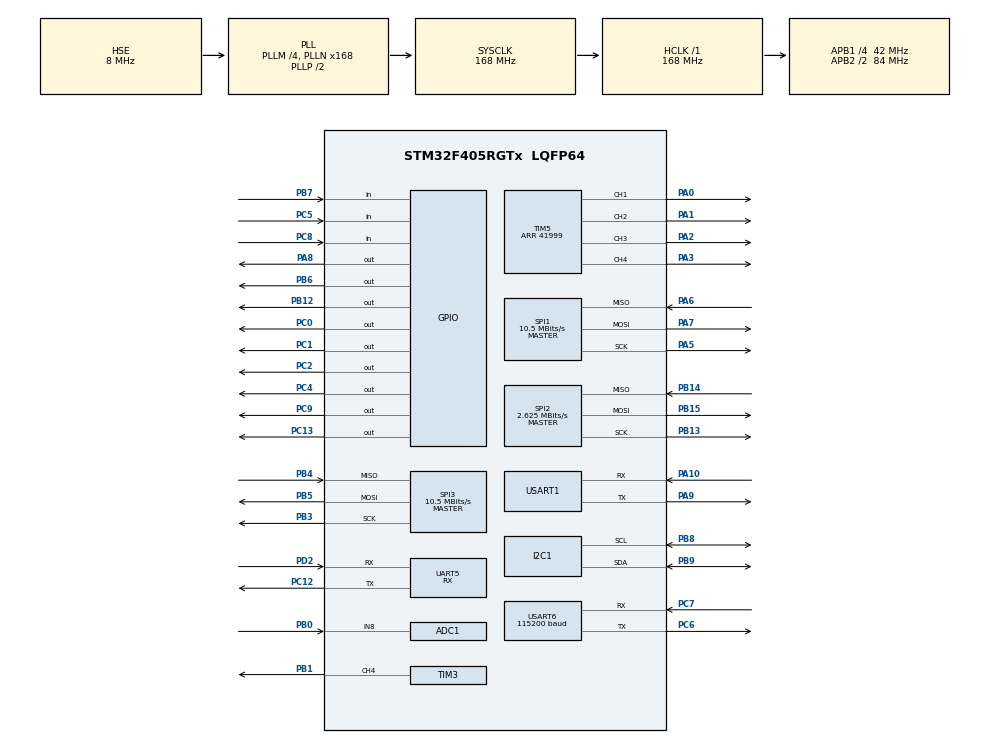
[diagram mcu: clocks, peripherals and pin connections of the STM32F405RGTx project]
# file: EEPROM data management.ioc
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ADC1.Channel-0\#ChannelRegularConversion=ADC_CHANNEL_8
ADC1.ClockPrescaler=ADC_CLOCK_SYNC_PCLK_DIV8
ADC1.ContinuousConvMode=ENABLE
ADC1.DMAContinuousRequests=ENABLE
ADC1.NbrOfConversionFlag=1
ADC1.Rank-0\#ChannelRegularConversion=1
ADC1.SamplingTime-0\#ChannelRegularConversion=ADC_SAMPLETIME_480CYCLES
ADC1.master=1
Dma.ADC1.0.Direction=DMA_PERIPH_TO_MEMORY
Dma.ADC1.0.FIFOMode=DMA_FIFOMODE_DISABLE
Dma.ADC1.0.Instance=DMA2_Stream0
Dma.ADC1.0.MemDataAlignment=DMA_MDATAALIGN_HALFWORD
Dma.ADC1.0.MemInc=DMA_MINC_DISABLE
Dma.ADC1.0.Mode=DMA_CIRCULAR
Dma.ADC1.0.PeriphDataAlignment=DMA_PDATAALIGN_HALFWORD
Dma.ADC1.0.PeriphInc=DMA_PINC_DISABLE
Dma.ADC1.0.Priority=DMA_PRIORITY_LOW
Dma.Request0=ADC1
I2C1.I2C_Mode=I2C_Fast
Mcu.Family=STM32F4
Mcu.Name=STM32F405RGTx
Mcu.Package=LQFP64
NVIC.DMA2_Stream0_IRQn=true\:0\:0\:false\:false\:true\:false\:true\:true
NVIC.PriorityGroup=NVIC_PRIORITYGROUP_4
NVIC.TIM7_IRQn=true\:0\:0\:false\:false\:true\:true\:true\:true
NVIC.UART5_IRQn=true\:0\:0\:false\:false\:true\:true\:true\:true
NVIC.USART1_IRQn=true\:0\:0\:false\:false\:true\:true\:true\:true
NVIC.USART6_IRQn=true\:0\:0\:false\:false\:true\:true\:true\:true
PA0-WKUP.Signal=S_TIM5_CH1
PA1.Signal=S_TIM5_CH2
PA10.Mode=Asynchronous
PA10.Signal=USART1_RX
PA2.Signal=S_TIM5_CH3
PA3.Signal=S_TIM5_CH4
PA5.Mode=Full_Duplex_Master
PA5.Signal=SPI1_SCK
PA6.Mode=Full_Duplex_Master
PA6.Signal=SPI1_MISO
PA7.Mode=Full_Duplex_Master
PA7.Signal=SPI1_MOSI
PA8.Signal=GPIO_Output
PA9.Mode=Asynchronous
PA9.Signal=USART1_TX
PB0.Signal=ADCx_IN8
PB1.Signal=S_TIM3_CH4
PB12.Signal=GPIO_Output
PB13.Mode=Full_Duplex_Master
PB13.Signal=SPI2_SCK
PB14.Mode=Full_Duplex_Master
PB14.Signal=SPI2_MISO
PB15.Mode=Full_Duplex_Master
PB15.Signal=SPI2_MOSI
PB3.Mode=Full_Duplex_Master
PB3.Signal=SPI3_SCK
PB4.Mode=Full_Duplex_Master
PB4.Signal=SPI3_MISO
PB5.Mode=Full_Duplex_Master
PB5.Signal=SPI3_MOSI
PB6.Signal=GPIO_Output
PB7.Signal=GPIO_Input
PB8.Mode=I2C
PB8.Signal=I2C1_SCL
PB9.Mode=I2C
PB9.Signal=I2C1_SDA
PC0.Signal=GPIO_Output
PC1.Signal=GPIO_Output
PC12.Mode=Asynchronous
PC12.Signal=UART5_TX
PC13-ANTI_TAMP.PinState=GPIO_PIN_SET
PC13-ANTI_TAMP.Signal=GPIO_Output
PC2.Signal=GPIO_Output
PC4.Signal=GPIO_Output
PC5.Signal=GPIO_Input
PC6.Mode=Asynchronous
PC6.Signal=USART6_TX
PC7.Mode=Asynchronous
PC7.Signal=USART6_RX
PC8.Signal=GPIO_Input
PC9.Signal=GPIO_Output
PD2.Mode=Asynchronous
PD2.Signal=UART5_RX
PH0-OSC_IN.Mode=HSE-External-Oscillator
PH0-OSC_IN.Signal=RCC_OSC_IN
PH1-OSC_OUT.Mode=HSE-External-Oscillator
PH1-OSC_OUT.Signal=RCC_OSC_OUT
ProjectManager.HeapSize=0x200
ProjectManager.StackSize=0x400
ProjectManager.TargetToolchain=STM32CubeIDE
RCC.48MHZClocksFreq_Value=84000000
RCC.AHBFreq_Value=168000000
RCC.APB1CLKDivider=RCC_HCLK_DIV4
RCC.APB1Freq_Value=42000000
RCC.APB1TimFreq_Value=84000000
RCC.APB2CLKDivider=RCC_HCLK_DIV2
RCC.APB2Freq_Value=84000000
RCC.APB2TimFreq_Value=168000000
RCC.CortexFreq_Value=168000000
RCC.HCLKFreq_Value=168000000
RCC.HSE_VALUE=8000000
RCC.HSI_VALUE=16000000
RCC.LSE_VALUE=32768
RCC.PLLM=4
RCC.PLLN=168
RCC.PLLSourceVirtual=RCC_PLLSOURCE_HSE
RCC.SYSCLKFreq_VALUE=168000000
RCC.SYSCLKSource=RCC_SYSCLKSOURCE_PLLCLK
RCC.VCOOutputFreq_Value=336000000
SH.ADCx_IN8.0=ADC1_IN8,IN8
SH.S_TIM3_CH4.0=TIM3_CH4,PWM Generation4 CH4
SH.S_TIM5_CH1.0=TIM5_CH1,PWM Generation1 CH1
SH.S_TIM5_CH2.0=TIM5_CH2,PWM Generation2 CH2
SH.S_TIM5_CH3.0=TIM5_CH3,PWM Generation3 CH3
SH.S_TIM5_CH4.0=TIM5_CH4,PWM Generation4 CH4
SPI1.BaudRatePrescaler=SPI_BAUDRATEPRESCALER_8
SPI1.CLKPhase=SPI_PHASE_2EDGE
SPI1.CLKPolarity=SPI_POLARITY_HIGH
SPI1.CalculateBaudRate=10.5 MBits/s
SPI1.DataSize=SPI_DATASIZE_8BIT
SPI1.Direction=SPI_DIRECTION_2LINES
SPI1.Mode=SPI_MODE_MASTER
SPI1.VirtualType=VM_MASTER
SPI2.BaudRatePrescaler=SPI_BAUDRATEPRESCALER_16
SPI2.CLKPhase=SPI_PHASE_2EDGE
SPI2.CLKPolarity=SPI_POLARITY_HIGH
SPI2.CalculateBaudRate=2.625 MBits/s
SPI2.Direction=SPI_DIRECTION_2LINES
SPI2.Mode=SPI_MODE_MASTER
SPI2.VirtualType=VM_MASTER
SPI3.BaudRatePrescaler=SPI_BAUDRATEPRESCALER_4
SPI3.CLKPhase=SPI_PHASE_2EDGE
SPI3.CLKPolarity=SPI_POLARITY_HIGH
SPI3.CalculateBaudRate=10.5 MBits/s
SPI3.Direction=SPI_DIRECTION_2LINES
SPI3.Mode=SPI_MODE_MASTER
SPI3.VirtualType=VM_MASTER
TIM3.AutoReloadPreload=TIM_AUTORELOAD_PRELOAD_ENABLE
TIM3.Channel-PWM\ Generation4\ CH4=TIM_CHANNEL_4
TIM3.OCFastMode_PWM-PWM\ Generation4\ CH4=TIM_OCFAST_ENABLE
TIM3.Period=20
TIM3.Prescaler=999
TIM3.Pulse-PWM\ Generation4\ CH4=10
TIM5.AutoReloadPreload=TIM_AUTORELOAD_PRELOAD_ENABLE
TIM5.Channel-PWM\ Generation1\ CH1=TIM_CHANNEL_1
TIM5.Channel-PWM\ Generation2\ CH2=TIM_CHANNEL_2
TIM5.Channel-PWM\ Generation3\ CH3=TIM_CHANNEL_3
TIM5.Channel-PWM\ Generation4\ CH4=TIM_CHANNEL_4
TIM5.OCFastMode_PWM-PWM\ Generation1\ CH1=TIM_OCFAST_ENABLE
TIM5.OCFastMode_PWM-PWM\ Generation2\ CH2=TIM_OCFAST_ENABLE
TIM5.OCFastMode_PWM-PWM\ Generation3\ CH3=TIM_OCFAST_ENABLE
TIM5.OCFastMode_PWM-PWM\ Generation4\ CH4=TIM_OCFAST_ENABLE
TIM5.Period=41999
TIM5.Pulse-PWM\ Generation1\ CH1=0
TIM5.Pulse-PWM\ Generation2\ CH2=0
TIM5.Pulse-PWM\ Generation3\ CH3=0
TIM7.AutoReloadPreload=TIM_AUTORELOAD_PRELOAD_ENABLE
TIM7.Period=1
TIM7.Prescaler=41999
UART5.Mode=MODE_RX
UART5.VirtualMode=Asynchronous
USART1.VirtualMode=VM_ASYNC
USART6.BaudRate=115200
USART6.VirtualMode=VM_ASYNC
VP_TIM3_VS_ClockSourceINT.Mode=Internal
VP_TIM5_VS_ClockSourceINT.Mode=Internal
VP_TIM7_VS_ClockSourceINT.Mode=Enable_Timer
board=custom

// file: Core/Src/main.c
/* USER CODE BEGIN Header */
/**
 ******************************************************************************
 * @file           : main.c
 * @brief          : Main program body
 ******************************************************************************
 * @attention
 *
 * Copyright (c) 2025 STMicroelectronics.
 * All rights reserved.
 *
 * This software is licensed under terms that can be found in the LICENSE file
 * in the root directory of this software component.
 * If no LICENSE file comes with this software, it is provided AS-IS.
 *
 ******************************************************************************
 */
/* USER CODE END Header */
#include "main.h"

/* USER CODE BEGIN Includes */
#include "BNO080.h"
#include "ICM20602.h"
#include "LPS22HH.h"
#include "FS-iA6B.h"
#include "AT24C08.h"
#include "Quaternion.h"
#include <stdio.h>
#include <string.h>
/* USER CODE END Includes */

/* USER CODE BEGIN PTD */
int _write(int file, char *p, int len)
{
	for (int i = 0; i < len; i ++)
	{
		LL_USART_TransmitData8(USART6, *(p + i));
		HAL_Delay(1);
	}
	return len;
}
/* USER CODE END PTD */

/* USER CODE BEGIN PD */
#define X 0.90f // LOW PASS FILTER CONSTANT (CLOSER TO 1 -> STRONGER THE FILTER)
/* USER CODE END PD */

ADC_HandleTypeDef hadc1;
DMA_HandleTypeDef hdma_adc1;

I2C_HandleTypeDef hi2c1;

UART_HandleTypeDef huart1;

/* USER CODE BEGIN PV */
extern uint8_t uart6_rx_flag;
extern uint8_t uart6_rx_data;

extern uint8_t ibus_rx_buf[36];
extern uint8_t ibus_rx_cplt_flag;

extern FSiA6B_iBus iBus;

extern I2C_HandleTypeDef hi2c;

extern uint8_t uart1_rx_data;

uint8_t radio_tx_buf[40];
uint8_t radio_rx_buf[20];
uint8_t radio_rx_cplt_flag;

extern uint8_t tim7_1ms_flag;
extern uint8_t tim7_20ms_flag;
extern uint8_t tim7_100ms_flag;
extern uint8_t tim7_1000ms_flag;

float batVolt;

float roll_in_kp;
float roll_in_ki;
float roll_in_kd;

float roll_out_kp;
float roll_out_ki;
float roll_out_kd;

float pitch_in_kp;
float pitch_in_ki;
float pitch_in_kd;

float pitch_out_kp;
float pitch_out_ki;
float pitch_out_kd;

float yaw_heading_kp;
float yaw_heading_ki;
float yaw_heading_kd;

float yaw_rate_kp;
float yaw_rate_ki;
float yaw_rate_kd;

unsigned char failsafe_flag = 0;
unsigned char low_bat_flag = 0;
/* USER CODE END PV */

void SystemClock_Config(void);
static void MX_GPIO_Init(void);
static void MX_DMA_Init(void);
static void MX_TIM3_Init(void);
static void MX_USART6_UART_Init(void);
static void MX_SPI2_Init(void);
static void MX_SPI1_Init(void);
static void MX_SPI3_Init(void);
static void MX_UART5_Init(void);
static void MX_TIM5_Init(void);
static void MX_I2C1_Init(void);
static void MX_ADC1_Init(void);
static void MX_USART1_UART_Init(void);
static void MX_TIM7_Init(void);
/* USER CODE BEGIN PFP */
void BNO080_Calibration(void);
int iBus_Connection_Status(void);
void ESC_Calibration(void);
int iBus_Throttle_Min(void);
void Encode_MSG_AHRS(unsigned char *radio_tx_buf);
void Encode_MSG_GPS(unsigned char *radio_tx_buf);
void Encode_MSG_PID_Gain(unsigned char *radio_tx_buf, unsigned char id, float p, float i, float d);
/* USER CODE END PFP */

int main(void)
{

	/* USER CODE BEGIN 1 */
	float q[4]; // array to store components of quaternion (x, y, z, w)
	float quatRadianAccuracy;
	unsigned short adcVal;
	short gyro_x_offset = 34, gyro_y_offset = -5, gyro_z_offset = -37;

	unsigned char motor_arm_flag = 0;
	unsigned short iBus_prev_SwA = 0;
	unsigned char iBus_rx_cnt = 0;
	unsigned short ccr1, ccr2, ccr3, ccr4;
	/* USER CODE END 1 */

	/* MCU Configuration--------------------------------------------------------*/

	/* Reset of all peripherals, Initializes the Flash interface and the Systick. */
	HAL_Init();

	/* Configure the system clock */
	SystemClock_Config();

	/* Initialize all configured peripherals */
	MX_GPIO_Init();
	MX_DMA_Init();
	MX_TIM3_Init();
	MX_USART6_UART_Init();
	MX_SPI2_Init();
	MX_SPI1_Init();
	MX_SPI3_Init();
	MX_UART5_Init();
	MX_TIM5_Init();
	MX_I2C1_Init();
	MX_ADC1_Init();
	MX_USART1_UART_Init();
	MX_TIM7_Init();
	/* USER CODE BEGIN 2 */
	/* enable timer for buzzer */
	LL_TIM_EnableCounter(TIM3);

	/* enable interrupt pins */
	LL_USART_EnableIT_RXNE(USART6);
	// TODO: enable interrupt pin for GPS module
	LL_USART_EnableIT_RXNE(UART5);
	// TODO: initialize M8N GPS module
	// initialize timer for generating PWM signals to motors
	LL_TIM_EnableCounter(TIM5);
	LL_TIM_CC_EnableChannel(TIM5, LL_TIM_CHANNEL_CH1);
	LL_TIM_CC_EnableChannel(TIM5, LL_TIM_CHANNEL_CH2);
	LL_TIM_CC_EnableChannel(TIM5, LL_TIM_CHANNEL_CH3);
	LL_TIM_CC_EnableChannel(TIM5, LL_TIM_CHANNEL_CH4);
	// direct memory access for ADC value
	HAL_ADC_Start_DMA(&hadc1, &adcVal, 1);
	HAL_UART_Receive_IT(&huart1, &uart1_rx_data, 1);

	LL_TIM_EnableCounter(TIM7); // 10Hz, 50Hz, 1kHz loop
	LL_TIM_EnableIT_UPDATE(TIM7);

	/* initialize external peripherals (sensors, telemetry) */

	TIM3->PSC = 1000;
	LL_TIM_CC_EnableChannel(TIM3, LL_TIM_CHANNEL_CH4);
	HAL_Delay(60);
	LL_TIM_CC_DisableChannel(TIM3, LL_TIM_CHANNEL_CH4);
	HAL_Delay(60);
	LL_TIM_CC_EnableChannel(TIM3, LL_TIM_CHANNEL_CH4);
	HAL_Delay(60);
	LL_TIM_CC_DisableChannel(TIM3, LL_TIM_CHANNEL_CH4);
	HAL_Delay(60);

	printf("checking sensor connection...\n");

	// initialize 9-axis sensor for rotation vector
	if(BNO080_Initialization())
	{
		LL_TIM_CC_EnableChannel(TIM3, LL_TIM_CHANNEL_CH4);

		TIM3->PSC = 1000;
		HAL_Delay(100);
		TIM3->PSC = 1500;
		HAL_Delay(100);
		TIM3->PSC = 2000;
		HAL_Delay(100);

		LL_TIM_CC_DisableChannel(TIM3, LL_TIM_CHANNEL_CH4);

		printf("\nBNO080 couldn't initialize. Shutting down...");
		while (1)
		{
			LL_TIM_CC_DisableChannel(TIM3, LL_TIM_CHANNEL_CH4);
			LL_GPIO_TogglePin(GPIOC, LL_GPIO_PIN_0);
			HAL_Delay(200);
			LL_TIM_CC_EnableChannel(TIM3, LL_TIM_CHANNEL_CH4);
			LL_GPIO_TogglePin(GPIOC, LL_GPIO_PIN_0);
			HAL_Delay(200);
		}
	}
	BNO080_enableRotationVector(2500);

	// initialize 6-axis sensor for angular velocity
	if(ICM20602_Initialization())
	{
		LL_TIM_CC_EnableChannel(TIM3, LL_TIM_CHANNEL_CH4);

		TIM3->PSC = 1000;
		HAL_Delay(100);
		TIM3->PSC = 1500;
		HAL_Delay(100);
		TIM3->PSC = 2000;
		HAL_Delay(100);

		LL_TIM_CC_DisableChannel(TIM3, LL_TIM_CHANNEL_CH4);

		printf("\nICM20602 couldn't initialize. Shutting down...");
		while (1)
		{
			LL_TIM_CC_DisableChannel(TIM3, LL_TIM_CHANNEL_CH4);
			LL_GPIO_TogglePin(GPIOC, LL_GPIO_PIN_1);
			HAL_Delay(200);
			LL_TIM_CC_EnableChannel(TIM3, LL_TIM_CHANNEL_CH4);
			LL_GPIO_TogglePin(GPIOC, LL_GPIO_PIN_1);
			HAL_Delay(200);
		}
	}

	// initialize barometric sensor for altitude
	if(LPS22HH_Initialization())
	{
		LL_TIM_CC_EnableChannel(TIM3, LL_TIM_CHANNEL_CH4);

		TIM3->PSC = 1000;
		HAL_Delay(100);
		TIM3->PSC = 1500;
		HAL_Delay(100);
		TIM3->PSC = 2000;
		HAL_Delay(100);

		LL_TIM_CC_DisableChannel(TIM3, LL_TIM_CHANNEL_CH4);

		printf("\nLPS22HH couldn't initialize. Shutting down...");
		while (1)
		{
			LL_TIM_CC_DisableChannel(TIM3, LL_TIM_CHANNEL_CH4);
			LL_GPIO_TogglePin(GPIOC, LL_GPIO_PIN_2);
			HAL_Delay(200);
			LL_TIM_CC_EnableChannel(TIM3, LL_TIM_CHANNEL_CH4);
			LL_GPIO_TogglePin(GPIOC, LL_GPIO_PIN_2);
			HAL_Delay(200);
		}
	}

	ICM20602_Writebyte(0x13, (gyro_x_offset*-2)>>8);
	ICM20602_Writebyte(0x14, (gyro_x_offset*-2));

	ICM20602_Writebyte(0x15, (gyro_y_offset*-2)>>8);
	ICM20602_Writebyte(0x16, (gyro_y_offset*-2));

	ICM20602_Writebyte(0x17, (gyro_z_offset*-2)>>8);
	ICM20602_Writebyte(0x18, (gyro_z_offset*-2));

	printf("loading PID gain...\n");

	if(EP_PID_Gain_Read(0, &roll_in_kp, &roll_in_ki, &roll_in_kd) || EP_PID_Gain_Read(1, &roll_out_kp, &roll_out_ki, &roll_out_kd) || EP_PID_Gain_Read(2, &pitch_in_kp, &pitch_in_ki, &pitch_in_kd) || EP_PID_Gain_Read(3, &pitch_out_kp, &pitch_out_ki, &pitch_out_kd) || EP_PID_Gain_Read(4, &yaw_heading_kp, &yaw_heading_ki, &yaw_heading_kd) || EP_PID_Gain_Read(5, &yaw_rate_kp, &yaw_rate_ki, &yaw_rate_kd))
	{
		LL_TIM_CC_EnableChannel(TIM3, LL_TIM_CHANNEL_CH4);

		TIM3->PSC = 1000;
		HAL_Delay(100);
		TIM3->PSC = 1500;
		HAL_Delay(100);
		TIM3->PSC = 2000;
		HAL_Delay(100);

		LL_TIM_CC_DisableChannel(TIM3, LL_TIM_CHANNEL_CH4);

		HAL_Delay(500);

		printf("\ncouldn't load PID gain...\n");
	}
	else
	{
		Encode_MSG_PID_Gain(&radio_tx_buf[0], 0, roll_in_kp, roll_in_ki, roll_in_kd);
		HAL_UART_Transmit(&huart1, &radio_tx_buf[0], 20, 10);

		Encode_MSG_PID_Gain(&radio_tx_buf[0], 1, roll_out_kp, roll_out_ki, roll_out_kd);
		HAL_UART_Transmit(&huart1, &radio_tx_buf[0], 20, 10);

		Encode_MSG_PID_Gain(&radio_tx_buf[0], 2, pitch_in_kp, pitch_in_ki, pitch_in_kd);
		HAL_UART_Transmit(&huart1, &radio_tx_buf[0], 20, 10);

		Encode_MSG_PID_Gain(&radio_tx_buf[0], 3, pitch_out_kp, pitch_out_ki, pitch_out_kd);
		HAL_UART_Transmit(&huart1, &radio_tx_buf[0], 20, 10);

		Encode_MSG_PID_Gain(&radio_tx_buf[0], 4, yaw_heading_kp, yaw_heading_ki, yaw_heading_kd);
		HAL_UART_Transmit(&huart1, &radio_tx_buf[0], 20, 10);

		Encode_MSG_PID_Gain(&radio_tx_buf[0], 5, yaw_rate_kp, yaw_rate_ki, yaw_rate_kd);
		HAL_UART_Transmit(&huart1, &radio_tx_buf[0], 20, 10);

		printf("\nall gains OK\n\n");
	}

	//block until iBus connection established
	while (!iBus_Connection_Status())
	{
		LL_TIM_CC_EnableChannel(TIM3, LL_TIM_CHANNEL_CH4);

		TIM3->PSC = 5000;
		HAL_Delay(500);
		LL_TIM_CC_DisableChannel(TIM3, LL_TIM_CHANNEL_CH4);
		HAL_Delay(500);
	}

	// calibration switch active?
	if (iBus.SwC == 2000)
	{
		LL_TIM_CC_EnableChannel(TIM3, LL_TIM_CHANNEL_CH4);

		TIM3->PSC = 1500;
		HAL_Delay(200);
		TIM3->PSC = 2000;
		HAL_Delay(200);
		TIM3->PSC = 1500;
		HAL_Delay(200);
		TIM3->PSC = 2000;
		HAL_Delay(200);

		LL_TIM_CC_DisableChannel(TIM3, LL_TIM_CHANNEL_CH4);

		ESC_Calibration();
		while (iBus.SwC != 1000)
		{
			iBus_Connection_Status();

			LL_TIM_CC_EnableChannel(TIM3, LL_TIM_CHANNEL_CH4);

			TIM3->PSC = 2000;
			HAL_Delay(200);
			TIM3->PSC = 2500;
			HAL_Delay(200);

			LL_TIM_CC_DisableChannel(TIM3, LL_TIM_CHANNEL_CH4);
		}
	}
	else if (iBus.SwC == 1500)
	{
		LL_TIM_CC_EnableChannel(TIM3, LL_TIM_CHANNEL_CH4);

		TIM3->PSC = 1500;
		HAL_Delay(200);
		TIM3->PSC = 2000;
		HAL_Delay(200);
		TIM3->PSC = 1500;
		HAL_Delay(200);
		TIM3->PSC = 2000;
		HAL_Delay(200);

		LL_TIM_CC_DisableChannel(TIM3, LL_TIM_CHANNEL_CH4);

		BNO080_Calibration();
		while (iBus.SwC != 1000)
		{
			iBus_Connection_Status();

			LL_TIM_CC_EnableChannel(TIM3, LL_TIM_CHANNEL_CH4);

			TIM3->PSC = 2000;
			HAL_Delay(200);
			TIM3->PSC = 2500;
			HAL_Delay(200);

			LL_TIM_CC_DisableChannel(TIM3, LL_TIM_CHANNEL_CH4);
		}
	}

	// ensure throttle stick is at minimum upon startup
	while (!iBus_Throttle_Min() || iBus.SwA == 2000)
	{
		LL_TIM_CC_EnableChannel(TIM3, LL_TIM_CHANNEL_CH4);

		TIM3->PSC = 1000;
		HAL_Delay(70);
		LL_TIM_CC_DisableChannel(TIM3, LL_TIM_CHANNEL_CH4);
		HAL_Delay(70);
	}

	// buzzer to indicate successful startup
	LL_TIM_CC_EnableChannel(TIM3, LL_TIM_CHANNEL_CH4);

	TIM3->PSC = 2000;
	HAL_Delay(100);
	TIM3->PSC = 1500;
	HAL_Delay(100);
	TIM3->PSC = 1000;
	HAL_Delay(100);

	LL_TIM_CC_DisableChannel(TIM3, LL_TIM_CHANNEL_CH4);

	printf("start...\n");

	/* USER CODE END 2 */

	/* Infinite loop */
	while (1)
	{

		/* USER CODE BEGIN 3 */
		if (tim7_1ms_flag)
		{
			tim7_1ms_flag = 0;

			ccr1 = 10500 + 500 + (iBus.LV - 1000) * 10 - (iBus.RV - 1500) * 5 + (iBus.RH - 1500) * 5 - (iBus.LH - 1500) * 5;
			ccr2 = 10500 + 500 + (iBus.LV - 1000) * 10 + (iBus.RV - 1500) * 5 + (iBus.RH - 1500) * 5 + (iBus.LH - 1500) * 5;
			ccr3 = 10500 + 500 + (iBus.LV - 1000) * 10 + (iBus.RV - 1500) * 5 - (iBus.RH - 1500) * 5 - (iBus.LH - 1500) * 5;
			ccr4 = 10500 + 500 + (iBus.LV - 1000) * 10 - (iBus.RV - 1500) * 5 - (iBus.RH - 1500) * 5 + (iBus.LH - 1500) * 5;

			printf("%f\t%f\n", BNO080_Pitch, ICM20602.gyro_x);
			printf("%f\t%f\n", BNO080_Roll, ICM20602.gyro_y);
			printf("%f\t%f\n", BNO080_Yaw, ICM20602.gyro_z);
		}

		if (iBus.SwA == 2000 && iBus_prev_SwA != 2000)
		{
			if (iBus.LV < 1010)
			{
				motor_arm_flag = 1;
			}
			else
			{
				LL_TIM_CC_EnableChannel(TIM3, LL_TIM_CHANNEL_CH4);

				TIM3->PSC = 1000;
				HAL_Delay(70);
				LL_TIM_CC_DisableChannel(TIM3, LL_TIM_CHANNEL_CH4);
				HAL_Delay(70);
			}
		}
		iBus_prev_SwA = iBus.SwA;

		if (iBus.SwA != 2000)
		{
			motor_arm_flag = 0;
		}

		if (motor_arm_flag)
		{
			if (!failsafe_flag)
			{
				TIM5->CCR1 = ccr1 > 21000 ? 21000 : ccr1 < 11000 ? 11000 : ccr1;
				TIM5->CCR2 = ccr2 > 21000 ? 21000 : ccr1 < 11000 ? 11000 : ccr2;
				TIM5->CCR3 = ccr3 > 21000 ? 21000 : ccr1 < 11000 ? 11000 : ccr3;
				TIM5->CCR4 = ccr4 > 21000 ? 21000 : ccr1 < 11000 ? 11000 : ccr4;
			}
			else
			{
				TIM5->CCR1 = 10500;
				TIM5->CCR2 = 10500;
				TIM5->CCR3 = 10500;
				TIM5->CCR4 = 10500;
			}
		}
		else
		{
			TIM5->CCR1 = 10500;
			TIM5->CCR2 = 10500;
			TIM5->CCR3 = 10500;
			TIM5->CCR4 = 10500;
		}

		if (radio_rx_cplt_flag)
		{
			radio_rx_cplt_flag = 0;

			if (iBus.SwA == 1000)
			{
				unsigned char chksum = 0xff;
				for (int i = 0; i < 19; i++) chksum = chksum - radio_rx_buf[i];

				if (chksum == radio_rx_buf[19])
				{
					LL_TIM_CC_EnableChannel(TIM3, LL_TIM_CHANNEL_CH4);

					TIM3->PSC = 1000;
					HAL_Delay(10);

					LL_TIM_CC_DisableChannel(TIM3, LL_TIM_CHANNEL_CH4);

					switch (radio_rx_buf[2])
					{
					case 0:
						roll_in_kp = *(float*)&radio_rx_buf[3];
						roll_in_ki = *(float*)&radio_rx_buf[7];
						roll_in_kd = *(float*)&radio_rx_buf[11];
						EP_PID_Gain_Write(radio_rx_buf[2], roll_in_kp, roll_in_ki, roll_in_kd);
						EP_PID_Gain_Read(radio_rx_buf[2], &roll_in_kp, &roll_in_ki, &roll_in_kd);
						Encode_MSG_PID_Gain(&radio_tx_buf[0], radio_rx_buf[2], roll_in_kp, roll_in_ki, roll_in_kd);
						HAL_UART_Transmit_IT(&huart1, &radio_tx_buf[0], 20);
					case 1:
						roll_out_kp = *(float*)&radio_rx_buf[3];
						roll_out_ki = *(float*)&radio_rx_buf[7];
						roll_out_kd = *(float*)&radio_rx_buf[11];
						EP_PID_Gain_Write(radio_rx_buf[2], roll_out_kp, roll_out_ki, roll_out_kd);
						EP_PID_Gain_Read(radio_rx_buf[2], &roll_out_kp, &roll_out_ki, &roll_out_kd);
						Encode_MSG_PID_Gain(&radio_tx_buf[0], radio_rx_buf[2], roll_out_kp, roll_out_ki, roll_out_kd);
						HAL_UART_Transmit_IT(&huart1, &radio_tx_buf[0], 20);
					case 2:
						pitch_in_kp = *(float*)&radio_rx_buf[3];
						pitch_in_ki = *(float*)&radio_rx_buf[7];
						pitch_in_kd = *(float*)&radio_rx_buf[11];
						EP_PID_Gain_Write(radio_rx_buf[2], pitch_in_kp, pitch_in_ki, pitch_in_kd);
						EP_PID_Gain_Read(radio_rx_buf[2], &pitch_in_kp, &pitch_in_ki, &pitch_in_kd);
						Encode_MSG_PID_Gain(&radio_tx_buf[0], radio_rx_buf[2], pitch_in_kp, pitch_in_ki, pitch_in_kd);
						HAL_UART_Transmit_IT(&huart1, &radio_tx_buf[0], 20);
					case 3:
						pitch_out_kp = *(float*)&radio_rx_buf[3];
						pitch_out_ki = *(float*)&radio_rx_buf[7];
						pitch_out_kd = *(float*)&radio_rx_buf[11];
						EP_PID_Gain_Write(radio_rx_buf[2], pitch_out_kp, pitch_out_ki, pitch_out_kd);
						EP_PID_Gain_Read(radio_rx_buf[2], &pitch_out_kp, &pitch_out_ki, &pitch_out_kd);
						Encode_MSG_PID_Gain(&radio_tx_buf[0], radio_rx_buf[2], pitch_out_kp, pitch_out_ki, pitch_out_kd);
						HAL_UART_Transmit_IT(&huart1, &radio_tx_buf[0], 20);
					case 4:
						yaw_heading_kp = *(float*)&radio_rx_buf[3];
						yaw_heading_ki = *(float*)&radio_rx_buf[7];
						yaw_heading_kd = *(float*)&radio_rx_buf[11];
						EP_PID_Gain_Write(radio_rx_buf[2], yaw_heading_kp, yaw_heading_ki, yaw_heading_kd);
						EP_PID_Gain_Read(radio_rx_buf[2], &yaw_heading_kp, &yaw_heading_ki, &yaw_heading_kd);
						Encode_MSG_PID_Gain(&radio_tx_buf[0], radio_rx_buf[2], yaw_heading_kp, yaw_heading_ki, yaw_heading_kd);
						HAL_UART_Transmit_IT(&huart1, &radio_tx_buf[0], 20);
					case 5:
						yaw_rate_kp = *(float*)&radio_rx_buf[3];
						yaw_rate_ki = *(float*)&radio_rx_buf[7];
						yaw_rate_kd = *(float*)&radio_rx_buf[11];
						EP_PID_Gain_Write(radio_rx_buf[2], yaw_rate_kp, yaw_rate_ki, yaw_rate_kd);
						EP_PID_Gain_Read(radio_rx_buf[2], &yaw_rate_kp, &yaw_rate_ki, &yaw_rate_kd);
						Encode_MSG_PID_Gain(&radio_tx_buf[0], radio_rx_buf[2], yaw_rate_kp, yaw_rate_ki, yaw_rate_kd);
						HAL_UART_Transmit_IT(&huart1, &radio_tx_buf[0], 20);
					case 0x10:
						switch (radio_rx_buf[3])
						{
						case 0:
							Encode_MSG_PID_Gain(&radio_tx_buf[0], radio_rx_buf[3], roll_in_kp, roll_in_ki, roll_in_kd);
							HAL_UART_Transmit(&huart1, &radio_tx_buf[0], 20, 10);
							break;
						case 1:
							Encode_MSG_PID_Gain(&radio_tx_buf[0], radio_rx_buf[3], roll_out_kp, roll_out_ki, roll_out_kd);
							HAL_UART_Transmit(&huart1, &radio_tx_buf[0], 20, 10);
							break;
						case 2:
							Encode_MSG_PID_Gain(&radio_tx_buf[0], radio_rx_buf[3], pitch_in_kp, pitch_in_ki, pitch_in_kd);
							HAL_UART_Transmit(&huart1, &radio_tx_buf[0], 20, 10);
							break;
						case 3:
							Encode_MSG_PID_Gain(&radio_tx_buf[0], radio_rx_buf[3], pitch_out_kp, pitch_out_ki, pitch_out_kd);
							HAL_UART_Transmit(&huart1, &radio_tx_buf[0], 20, 10);
							break;
						case 4:
							Encode_MSG_PID_Gain(&radio_tx_buf[0], radio_rx_buf[3], yaw_heading_kp, yaw_heading_ki, yaw_heading_kd);
							HAL_UART_Transmit(&huart1, &radio_tx_buf[0], 20, 10);
							break;
						case 5:
							Encode_MSG_PID_Gain(&radio_tx_buf[0], radio_rx_buf[3], yaw_rate_kp, yaw_rate_ki, yaw_rate_kd);
							HAL_UART_Transmit(&huart1, &radio_tx_buf[0], 20, 10);
							break;
						case 6:
							Encode_MSG_PID_Gain(&radio_tx_buf[0], 0, roll_in_kp, roll_in_ki, roll_in_kd);
							HAL_UART_Transmit(&huart1, &radio_tx_buf[0], 20, 10);
							Encode_MSG_PID_Gain(&radio_tx_buf[0], 1, roll_out_kp, roll_out_ki, roll_out_kd);
							HAL_UART_Transmit(&huart1, &radio_tx_buf[0], 20, 10);
							Encode_MSG_PID_Gain(&radio_tx_buf[0], 2, pitch_in_kp, pitch_in_ki, pitch_in_kd);
							HAL_UART_Transmit(&huart1, &radio_tx_buf[0], 20, 10);
							Encode_MSG_PID_Gain(&radio_tx_buf[0], 3, pitch_out_kp, pitch_out_ki, pitch_out_kd);
							HAL_UART_Transmit(&huart1, &radio_tx_buf[0], 20, 10);
							Encode_MSG_PID_Gain(&radio_tx_buf[0], 4, yaw_heading_kp, yaw_heading_ki, yaw_heading_kd);
							HAL_UART_Transmit(&huart1, &radio_tx_buf[0], 20, 10);
							Encode_MSG_PID_Gain(&radio_tx_buf[0], 5, yaw_rate_kp, yaw_rate_ki, yaw_rate_kd);
							HAL_UART_Transmit(&huart1, &radio_tx_buf[0], 20, 10);
							break;
						}
						break;
					}
				}
			}
		}

		if (tim7_20ms_flag && !tim7_100ms_flag)
		{
			tim7_20ms_flag = 0;

			Encode_MSG_AHRS(&radio_tx_buf[0]);

			HAL_UART_Transmit_IT(&huart1, &radio_tx_buf[0], 20);
		}
		else if (tim7_20ms_flag && tim7_100ms_flag)
		{
			tim7_20ms_flag = 0;
			tim7_100ms_flag = 0;

			Encode_MSG_AHRS(&radio_tx_buf[0]);
			Encode_MSG_GPS(&radio_tx_buf[20]);

			HAL_UART_Transmit_IT(&huart1, &radio_tx_buf[0], 40);
		}

		// convert ADC value to Voltage value
		batVolt = adcVal * 0.003619f;

		if (batVolt < 10.0f)
		{
			low_bat_flag = 1;
		}
		else
		{
			low_bat_flag = 0;
		}

		if (BNO080_dataAvailable())
		{
			q[0] = BNO080_getQuatI();
			q[1] = BNO080_getQuatJ();
			q[2] = BNO080_getQuatK();
			q[3] = BNO080_getQuatReal();
			quatRadianAccuracy = BNO080_getQuatRadianAccuracy();

			Quaternion_Update(&q[0]);

			//printf("%.2f %.2f\n", BNO080_Roll, BNO080_Pitch);
		}

		if (ICM20602_DataReady())
		{
			ICM20602_Get3AxisGyroRawData(&ICM20602.gyro_x_raw);

			ICM20602.gyro_x = ICM20602.gyro_x_raw * 2000.f / 32768.f;
			ICM20602.gyro_y = ICM20602.gyro_y_raw * 2000.f / 32768.f;
			ICM20602.gyro_z = ICM20602.gyro_z_raw * 2000.f / 32768.f;

			//printf("%d %d %d\n", ICM20602.gyro_x_raw, ICM20602.gyro_y_raw, ICM20602.gyro_z_raw);
			//printf("%d %d %d\n", (int)(ICM20602->gyro_x*100), (int)(ICM20602->gyro_y*100), (int)(ICM20602->gyro_z*100));
		}

		if (LPS22HH_DataReady())
		{
			LPS22HH_GetPressure(&LPS22HH.pressure_raw);
			LPS22HH_GetTemperature(&LPS22HH.temperature_raw);

			LPS22HH.baroAlt = getAltitude2(LPS22HH.pressure_raw/4096.f, LPS22HH.temperature_raw/100.f); // altitude in cms

			LPS22HH.baroAltFilt = LPS22HH.baroAltFilt * X + LPS22HH.baroAlt * (1.0f - X);

			//printf("%d %d\n", (int) (LPS22HH.baroAlt*100), (int) (LPS22HH.baroAltFilt*100));
		}

		if (ibus_rx_cplt_flag)
		{
			ibus_rx_cplt_flag = 0;
			if (iBus_Check_CHKSUM(&ibus_rx_buf[0], 32))
			{
				LL_GPIO_TogglePin(GPIOC, LL_GPIO_PIN_2); // toggle LED if iBus frame checksum successful --> intact iBus frame

				iBus_Parse(&ibus_rx_buf[0], &iBus); // parse and store switch/gimbal data in iBus structure

				iBus_rx_cnt++;

				// failsafe for shutting down upon abrupt disconnect between transmitter and receiver
				if (iBus_isActiveFailsafe(&iBus))
				{
					LL_TIM_CC_EnableChannel(TIM3, LL_TIM_CHANNEL_CH4);
					failsafe_flag = 1;

				}
				else
				{
					LL_TIM_CC_DisableChannel(TIM3, LL_TIM_CHANNEL_CH4);
					failsafe_flag = 0;
				}

				//        	printf("%d\t%d\t%d\t%d\t%d\t%d\t\n", iBus.RH, iBus.RV, iBus.LV, iBus.LH, iBus.SwA, iBus.SwC);
				//
				//        	HAL_Delay(30);
			}
		}

		if (tim7_1000ms_flag)
		{
			tim7_1000ms_flag = 0;
			if (!iBus_rx_cnt)
			{
				failsafe_flag = 2;
			}
		}

		if (failsafe_flag == 1 || failsafe_flag == 2 || low_bat_flag == 1 || iBus.SwC == 2000)
		{
			LL_TIM_CC_EnableChannel(TIM3, LL_TIM_CHANNEL_CH4);
		}
		else
		{
			LL_TIM_CC_DisableChannel(TIM3, LL_TIM_CHANNEL_CH4);
		}
	}
	/* USER CODE END 3 */
}

void SystemClock_Config(void)
{
	RCC_OscInitTypeDef RCC_OscInitStruct = {0};
	RCC_ClkInitTypeDef RCC_ClkInitStruct = {0};

	/** Configure the main internal regulator output voltage
	 */
	__HAL_RCC_PWR_CLK_ENABLE();
	__HAL_PWR_VOLTAGESCALING_CONFIG(PWR_REGULATOR_VOLTAGE_SCALE1);

	/** Initializes the RCC Oscillators according to the specified parameters
	 * in the RCC_OscInitTypeDef structure.
	 */
	RCC_OscInitStruct.OscillatorType = RCC_OSCILLATORTYPE_HSE;
	RCC_OscInitStruct.HSEState = RCC_HSE_ON;
	RCC_OscInitStruct.PLL.PLLState = RCC_PLL_ON;
	RCC_OscInitStruct.PLL.PLLSource = RCC_PLLSOURCE_HSE;
	RCC_OscInitStruct.PLL.PLLM = 4;
	RCC_OscInitStruct.PLL.PLLN = 168;
	RCC_OscInitStruct.PLL.PLLP = RCC_PLLP_DIV2;
	RCC_OscInitStruct.PLL.PLLQ = 4;
	if (HAL_RCC_OscConfig(&RCC_OscInitStruct) != HAL_OK)
	{
		Error_Handler();
	}

	/** Initializes the CPU, AHB and APB buses clocks
	 */
	RCC_ClkInitStruct.ClockType = RCC_CLOCKTYPE_HCLK|RCC_CLOCKTYPE_SYSCLK
			|RCC_CLOCKTYPE_PCLK1|RCC_CLOCKTYPE_PCLK2;
	RCC_ClkInitStruct.SYSCLKSource = RCC_SYSCLKSOURCE_PLLCLK;
	RCC_ClkInitStruct.AHBCLKDivider = RCC_SYSCLK_DIV1;
	RCC_ClkInitStruct.APB1CLKDivider = RCC_HCLK_DIV4;
	RCC_ClkInitStruct.APB2CLKDivider = RCC_HCLK_DIV2;

	if (HAL_RCC_ClockConfig(&RCC_ClkInitStruct, FLASH_LATENCY_5) != HAL_OK)
	{
		Error_Handler();
	}
}

static void MX_ADC1_Init(void)
{

	ADC_ChannelConfTypeDef sConfig = {0};

	/** Configure the global features of the ADC (Clock, Resolution, Data Alignment and number of conversion)
	 */
	hadc1.Instance = ADC1;
	hadc1.Init.ClockPrescaler = ADC_CLOCK_SYNC_PCLK_DIV8;
	hadc1.Init.Resolution = ADC_RESOLUTION_12B;
	hadc1.Init.ScanConvMode = DISABLE;
	hadc1.Init.ContinuousConvMode = ENABLE;
	hadc1.Init.DiscontinuousConvMode = DISABLE;
	hadc1.Init.ExternalTrigConvEdge = ADC_EXTERNALTRIGCONVEDGE_NONE;
	hadc1.Init.ExternalTrigConv = ADC_SOFTWARE_START;
	hadc1.Init.DataAlign = ADC_DATAALIGN_RIGHT;
	hadc1.Init.NbrOfConversion = 1;
	hadc1.Init.DMAContinuousRequests = ENABLE;
	hadc1.Init.EOCSelection = ADC_EOC_SINGLE_CONV;
	if (HAL_ADC_Init(&hadc1) != HAL_OK)
	{
		Error_Handler();
	}

	/** Configure for the selected ADC regular channel its corresponding rank in the sequencer and its sample time.
	 */
	sConfig.Channel = ADC_CHANNEL_8;
	sConfig.Rank = 1;
	sConfig.SamplingTime = ADC_SAMPLETIME_480CYCLES;
	if (HAL_ADC_ConfigChannel(&hadc1, &sConfig) != HAL_OK)
	{
		Error_Handler();
	}

}

static void MX_I2C1_Init(void)
{

	hi2c1.Instance = I2C1;
	hi2c1.Init.ClockSpeed = 400000;
	hi2c1.Init.DutyCycle = I2C_DUTYCYCLE_2;
	hi2c1.Init.OwnAddress1 = 0;
	hi2c1.Init.AddressingMode = I2C_ADDRESSINGMODE_7BIT;
	hi2c1.Init.DualAddressMode = I2C_DUALADDRESS_DISABLE;
	hi2c1.Init.OwnAddress2 = 0;
	hi2c1.Init.GeneralCallMode = I2C_GENERALCALL_DISABLE;
	hi2c1.Init.NoStretchMode = I2C_NOSTRETCH_DISABLE;
	if (HAL_I2C_Init(&hi2c1) != HAL_OK)
	{
		Error_Handler();
	}
	/* USER CODE BEGIN I2C1_Init 2 */
	hi2c = hi2c1;
	/* USER CODE END I2C1_Init 2 */

}

static void MX_SPI1_Init(void)
{

	LL_SPI_InitTypeDef SPI_InitStruct = {0};

	LL_GPIO_InitTypeDef GPIO_InitStruct = {0};

	/* Peripheral clock enable */
	LL_APB2_GRP1_EnableClock(LL_APB2_GRP1_PERIPH_SPI1);

	LL_AHB1_GRP1_EnableClock(LL_AHB1_GRP1_PERIPH_GPIOA);
	/**SPI1 GPIO Configuration
  PA5   ------> SPI1_SCK
  PA6   ------> SPI1_MISO
  PA7   ------> SPI1_MOSI
	 */
	GPIO_InitStruct.Pin = LL_GPIO_PIN_5|LL_GPIO_PIN_6|LL_GPIO_PIN_7;
	GPIO_InitStruct.Mode = LL_GPIO_MODE_ALTERNATE;
	GPIO_InitStruct.Speed = LL_GPIO_SPEED_FREQ_VERY_HIGH;
	GPIO_InitStruct.OutputType = LL_GPIO_OUTPUT_PUSHPULL;
	GPIO_InitStruct.Pull = LL_GPIO_PULL_NO;
	GPIO_InitStruct.Alternate = LL_GPIO_AF_5;
	LL_GPIO_Init(GPIOA, &GPIO_InitStruct);

	/* SPI1 parameter configuration*/
	SPI_InitStruct.TransferDirection = LL_SPI_FULL_DUPLEX;
	SPI_InitStruct.Mode = LL_SPI_MODE_MASTER;
	SPI_InitStruct.DataWidth = LL_SPI_DATAWIDTH_8BIT;
	SPI_InitStruct.ClockPolarity = LL_SPI_POLARITY_HIGH;
	SPI_InitStruct.ClockPhase = LL_SPI_PHASE_2EDGE;
	SPI_InitStruct.NSS = LL_SPI_NSS_SOFT;
	SPI_InitStruct.BaudRate = LL_SPI_BAUDRATEPRESCALER_DIV8;
	SPI_InitStruct.BitOrder = LL_SPI_MSB_FIRST;
	SPI_InitStruct.CRCCalculation = LL_SPI_CRCCALCULATION_DISABLE;
	SPI_InitStruct.CRCPoly = 10;
	LL_SPI_Init(SPI1, &SPI_InitStruct);
	LL_SPI_SetStandard(SPI1, LL_SPI_PROTOCOL_MOTOROLA);

}

static void MX_SPI2_Init(void)
{

	LL_SPI_InitTypeDef SPI_InitStruct = {0};

	LL_GPIO_InitTypeDef GPIO_InitStruct = {0};

	/* Peripheral clock enable */
	LL_APB1_GRP1_EnableClock(LL_APB1_GRP1_PERIPH_SPI2);

	LL_AHB1_GRP1_EnableClock(LL_AHB1_GRP1_PERIPH_GPIOB);
	/**SPI2 GPIO Configuration
  PB13   ------> SPI2_SCK
  PB14   ------> SPI2_MISO
  PB15   ------> SPI2_MOSI
	 */
	GPIO_InitStruct.Pin = LL_GPIO_PIN_13|LL_GPIO_PIN_14|LL_GPIO_PIN_15;
	GPIO_InitStruct.Mode = LL_GPIO_MODE_ALTERNATE;
	GPIO_InitStruct.Speed = LL_GPIO_SPEED_FREQ_VERY_HIGH;
	GPIO_InitStruct.OutputType = LL_GPIO_OUTPUT_PUSHPULL;
	GPIO_InitStruct.Pull = LL_GPIO_PULL_NO;
	GPIO_InitStruct.Alternate = LL_GPIO_AF_5;
	LL_GPIO_Init(GPIOB, &GPIO_InitStruct);

	/* SPI2 parameter configuration*/
	SPI_InitStruct.TransferDirection = LL_SPI_FULL_DUPLEX;
	SPI_InitStruct.Mode = LL_SPI_MODE_MASTER;
	SPI_InitStruct.DataWidth = LL_SPI_DATAWIDTH_8BIT;
	SPI_InitStruct.ClockPolarity = LL_SPI_POLARITY_HIGH;
	SPI_InitStruct.ClockPhase = LL_SPI_PHASE_2EDGE;
	SPI_InitStruct.NSS = LL_SPI_NSS_SOFT;
	SPI_InitStruct.BaudRate = LL_SPI_BAUDRATEPRESCALER_DIV16;
	SPI_InitStruct.BitOrder = LL_SPI_MSB_FIRST;
	SPI_InitStruct.CRCCalculation = LL_SPI_CRCCALCULATION_DISABLE;
	SPI_InitStruct.CRCPoly = 10;
	LL_SPI_Init(SPI2, &SPI_InitStruct);
	LL_SPI_SetStandard(SPI2, LL_SPI_PROTOCOL_MOTOROLA);

}

static void MX_SPI3_Init(void)
{

	LL_SPI_InitTypeDef SPI_InitStruct = {0};

	LL_GPIO_InitTypeDef GPIO_InitStruct = {0};

	/* Peripheral clock enable */
	LL_APB1_GRP1_EnableClock(LL_APB1_GRP1_PERIPH_SPI3);

	LL_AHB1_GRP1_EnableClock(LL_AHB1_GRP1_PERIPH_GPIOB);
	/**SPI3 GPIO Configuration
  PB3   ------> SPI3_SCK
  PB4   ------> SPI3_MISO
  PB5   ------> SPI3_MOSI
	 */
	GPIO_InitStruct.Pin = LL_GPIO_PIN_3|LL_GPIO_PIN_4|LL_GPIO_PIN_5;
	GPIO_InitStruct.Mode = LL_GPIO_MODE_ALTERNATE;
	GPIO_InitStruct.Speed = LL_GPIO_SPEED_FREQ_VERY_HIGH;
	GPIO_InitStruct.OutputType = LL_GPIO_OUTPUT_PUSHPULL;
	GPIO_InitStruct.Pull = LL_GPIO_PULL_NO;
	GPIO_InitStruct.Alternate = LL_GPIO_AF_6;
	LL_GPIO_Init(GPIOB, &GPIO_InitStruct);

	/* SPI3 parameter configuration*/
	SPI_InitStruct.TransferDirection = LL_SPI_FULL_DUPLEX;
	SPI_InitStruct.Mode = LL_SPI_MODE_MASTER;
	SPI_InitStruct.DataWidth = LL_SPI_DATAWIDTH_8BIT;
	SPI_InitStruct.ClockPolarity = LL_SPI_POLARITY_HIGH;
	SPI_InitStruct.ClockPhase = LL_SPI_PHASE_2EDGE;
	SPI_InitStruct.NSS = LL_SPI_NSS_SOFT;
	SPI_InitStruct.BaudRate = LL_SPI_BAUDRATEPRESCALER_DIV4;
	SPI_InitStruct.BitOrder = LL_SPI_MSB_FIRST;
	SPI_InitStruct.CRCCalculation = LL_SPI_CRCCALCULATION_DISABLE;
	SPI_InitStruct.CRCPoly = 10;
	LL_SPI_Init(SPI3, &SPI_InitStruct);
	LL_SPI_SetStandard(SPI3, LL_SPI_PROTOCOL_MOTOROLA);

}

static void MX_TIM3_Init(void)
{

	LL_TIM_InitTypeDef TIM_InitStruct = {0};
	LL_TIM_OC_InitTypeDef TIM_OC_InitStruct = {0};

	LL_GPIO_InitTypeDef GPIO_InitStruct = {0};

	/* Peripheral clock enable */
	LL_APB1_GRP1_EnableClock(LL_APB1_GRP1_PERIPH_TIM3);

	TIM_InitStruct.Prescaler = 999;
	TIM_InitStruct.CounterMode = LL_TIM_COUNTERMODE_UP;
	TIM_InitStruct.Autoreload = 20;
	TIM_InitStruct.ClockDivision = LL_TIM_CLOCKDIVISION_DIV1;
	LL_TIM_Init(TIM3, &TIM_InitStruct);
	LL_TIM_EnableARRPreload(TIM3);
	LL_TIM_SetClockSource(TIM3, LL_TIM_CLOCKSOURCE_INTERNAL);
	LL_TIM_OC_EnablePreload(TIM3, LL_TIM_CHANNEL_CH4);
	TIM_OC_InitStruct.OCMode = LL_TIM_OCMODE_PWM1;
	TIM_OC_InitStruct.OCState = LL_TIM_OCSTATE_DISABLE;
	TIM_OC_InitStruct.OCNState = LL_TIM_OCSTATE_DISABLE;
	TIM_OC_InitStruct.CompareValue = 10;
	TIM_OC_InitStruct.OCPolarity = LL_TIM_OCPOLARITY_HIGH;
	LL_TIM_OC_Init(TIM3, LL_TIM_CHANNEL_CH4, &TIM_OC_InitStruct);
	LL_TIM_OC_EnableFast(TIM3, LL_TIM_CHANNEL_CH4);
	LL_TIM_SetTriggerOutput(TIM3, LL_TIM_TRGO_RESET);
	LL_TIM_DisableMasterSlaveMode(TIM3);
	LL_AHB1_GRP1_EnableClock(LL_AHB1_GRP1_PERIPH_GPIOB);
	/**TIM3 GPIO Configuration
  PB1   ------> TIM3_CH4
	 */
	GPIO_InitStruct.Pin = LL_GPIO_PIN_1;
	GPIO_InitStruct.Mode = LL_GPIO_MODE_ALTERNATE;
	GPIO_InitStruct.Speed = LL_GPIO_SPEED_FREQ_LOW;
	GPIO_InitStruct.OutputType = LL_GPIO_OUTPUT_PUSHPULL;
	GPIO_InitStruct.Pull = LL_GPIO_PULL_NO;
	GPIO_InitStruct.Alternate = LL_GPIO_AF_2;
	LL_GPIO_Init(GPIOB, &GPIO_InitStruct);

}

static void MX_TIM5_Init(void)
{

	LL_TIM_InitTypeDef TIM_InitStruct = {0};
	LL_TIM_OC_InitTypeDef TIM_OC_InitStruct = {0};

	LL_GPIO_InitTypeDef GPIO_InitStruct = {0};

	/* Peripheral clock enable */
	LL_APB1_GRP1_EnableClock(LL_APB1_GRP1_PERIPH_TIM5);

	TIM_InitStruct.Prescaler = 0;
	TIM_InitStruct.CounterMode = LL_TIM_COUNTERMODE_UP;
	TIM_InitStruct.Autoreload = 41999;
	TIM_InitStruct.ClockDivision = LL_TIM_CLOCKDIVISION_DIV1;
	LL_TIM_Init(TIM5, &TIM_InitStruct);
	LL_TIM_EnableARRPreload(TIM5);
	LL_TIM_SetClockSource(TIM5, LL_TIM_CLOCKSOURCE_INTERNAL);
	LL_TIM_OC_EnablePreload(TIM5, LL_TIM_CHANNEL_CH1);
	TIM_OC_InitStruct.OCMode = LL_TIM_OCMODE_PWM1;
	TIM_OC_InitStruct.OCState = LL_TIM_OCSTATE_DISABLE;
	TIM_OC_InitStruct.OCNState = LL_TIM_OCSTATE_DISABLE;
	TIM_OC_InitStruct.CompareValue = 0;
	TIM_OC_InitStruct.OCPolarity = LL_TIM_OCPOLARITY_HIGH;
	LL_TIM_OC_Init(TIM5, LL_TIM_CHANNEL_CH1, &TIM_OC_InitStruct);
	LL_TIM_OC_EnableFast(TIM5, LL_TIM_CHANNEL_CH1);
	LL_TIM_OC_EnablePreload(TIM5, LL_TIM_CHANNEL_CH2);
	LL_TIM_OC_Init(TIM5, LL_TIM_CHANNEL_CH2, &TIM_OC_InitStruct);
	LL_TIM_OC_EnableFast(TIM5, LL_TIM_CHANNEL_CH2);
	LL_TIM_OC_EnablePreload(TIM5, LL_TIM_CHANNEL_CH3);
	LL_TIM_OC_Init(TIM5, LL_TIM_CHANNEL_CH3, &TIM_OC_InitStruct);
	LL_TIM_OC_EnableFast(TIM5, LL_TIM_CHANNEL_CH3);
	LL_TIM_OC_EnablePreload(TIM5, LL_TIM_CHANNEL_CH4);
	LL_TIM_OC_Init(TIM5, LL_TIM_CHANNEL_CH4, &TIM_OC_InitStruct);
	LL_TIM_OC_EnableFast(TIM5, LL_TIM_CHANNEL_CH4);
	LL_TIM_SetTriggerOutput(TIM5, LL_TIM_TRGO_RESET);
	LL_TIM_DisableMasterSlaveMode(TIM5);
	LL_AHB1_GRP1_EnableClock(LL_AHB1_GRP1_PERIPH_GPIOA);
	/**TIM5 GPIO Configuration
  PA0-WKUP   ------> TIM5_CH1
  PA1   ------> TIM5_CH2
  PA2   ------> TIM5_CH3
  PA3   ------> TIM5_CH4
	 */
	GPIO_InitStruct.Pin = LL_GPIO_PIN_0|LL_GPIO_PIN_1|LL_GPIO_PIN_2|LL_GPIO_PIN_3;
	GPIO_InitStruct.Mode = LL_GPIO_MODE_ALTERNATE;
	GPIO_InitStruct.Speed = LL_GPIO_SPEED_FREQ_LOW;
	GPIO_InitStruct.OutputType = LL_GPIO_OUTPUT_PUSHPULL;
	GPIO_InitStruct.Pull = LL_GPIO_PULL_NO;
	GPIO_InitStruct.Alternate = LL_GPIO_AF_2;
	LL_GPIO_Init(GPIOA, &GPIO_InitStruct);

}

static void MX_TIM7_Init(void)
{

	LL_TIM_InitTypeDef TIM_InitStruct = {0};

	/* Peripheral clock enable */
	LL_APB1_GRP1_EnableClock(LL_APB1_GRP1_PERIPH_TIM7);

	/* TIM7 interrupt Init */
	NVIC_SetPriority(TIM7_IRQn, NVIC_EncodePriority(NVIC_GetPriorityGrouping(),0, 0));
	NVIC_EnableIRQ(TIM7_IRQn);

	TIM_InitStruct.Prescaler = 41999;
	TIM_InitStruct.CounterMode = LL_TIM_COUNTERMODE_UP;
	TIM_InitStruct.Autoreload = 1;
	LL_TIM_Init(TIM7, &TIM_InitStruct);
	LL_TIM_EnableARRPreload(TIM7);
	LL_TIM_SetTriggerOutput(TIM7, LL_TIM_TRGO_RESET);
	LL_TIM_DisableMasterSlaveMode(TIM7);

}

static void MX_UART5_Init(void)
{

	LL_USART_InitTypeDef USART_InitStruct = {0};

	LL_GPIO_InitTypeDef GPIO_InitStruct = {0};

	/* Peripheral clock enable */
	LL_APB1_GRP1_EnableClock(LL_APB1_GRP1_PERIPH_UART5);

	LL_AHB1_GRP1_EnableClock(LL_AHB1_GRP1_PERIPH_GPIOC);
	LL_AHB1_GRP1_EnableClock(LL_AHB1_GRP1_PERIPH_GPIOD);
	/**UART5 GPIO Configuration
  PC12   ------> UART5_TX
  PD2   ------> UART5_RX
	 */
	GPIO_InitStruct.Pin = LL_GPIO_PIN_12;
	GPIO_InitStruct.Mode = LL_GPIO_MODE_ALTERNATE;
	GPIO_InitStruct.Speed = LL_GPIO_SPEED_FREQ_VERY_HIGH;
	GPIO_InitStruct.OutputType = LL_GPIO_OUTPUT_PUSHPULL;
	GPIO_InitStruct.Pull = LL_GPIO_PULL_NO;
	GPIO_InitStruct.Alternate = LL_GPIO_AF_8;
	LL_GPIO_Init(GPIOC, &GPIO_InitStruct);

	GPIO_InitStruct.Pin = LL_GPIO_PIN_2;
	GPIO_InitStruct.Mode = LL_GPIO_MODE_ALTERNATE;
	GPIO_InitStruct.Speed = LL_GPIO_SPEED_FREQ_VERY_HIGH;
	GPIO_InitStruct.OutputType = LL_GPIO_OUTPUT_PUSHPULL;
	GPIO_InitStruct.Pull = LL_GPIO_PULL_NO;
	GPIO_InitStruct.Alternate = LL_GPIO_AF_8;
	LL_GPIO_Init(GPIOD, &GPIO_InitStruct);

	/* UART5 interrupt Init */
	NVIC_SetPriority(UART5_IRQn, NVIC_EncodePriority(NVIC_GetPriorityGrouping(),0, 0));
	NVIC_EnableIRQ(UART5_IRQn);

	USART_InitStruct.BaudRate = 115200;
	USART_InitStruct.DataWidth = LL_USART_DATAWIDTH_8B;
	USART_InitStruct.StopBits = LL_USART_STOPBITS_1;
	USART_InitStruct.Parity = LL_USART_PARITY_NONE;
	USART_InitStruct.TransferDirection = LL_USART_DIRECTION_RX;
	USART_InitStruct.HardwareFlowControl = LL_USART_HWCONTROL_NONE;
	USART_InitStruct.OverSampling = LL_USART_OVERSAMPLING_16;
	LL_USART_Init(UART5, &USART_InitStruct);
	LL_USART_ConfigAsyncMode(UART5);
	LL_USART_Enable(UART5);

}

static void MX_USART1_UART_Init(void)
{

	huart1.Instance = USART1;
	huart1.Init.BaudRate = 115200;
	huart1.Init.WordLength = UART_WORDLENGTH_8B;
	huart1.Init.StopBits = UART_STOPBITS_1;
	huart1.Init.Parity = UART_PARITY_NONE;
	huart1.Init.Mode = UART_MODE_TX_RX;
	huart1.Init.HwFlowCtl = UART_HWCONTROL_NONE;
	huart1.Init.OverSampling = UART_OVERSAMPLING_16;
	if (HAL_UART_Init(&huart1) != HAL_OK)
	{
		Error_Handler();
	}

}

static void MX_USART6_UART_Init(void)
{

	LL_USART_InitTypeDef USART_InitStruct = {0};

	LL_GPIO_InitTypeDef GPIO_InitStruct = {0};

	/* Peripheral clock enable */
	LL_APB2_GRP1_EnableClock(LL_APB2_GRP1_PERIPH_USART6);

	LL_AHB1_GRP1_EnableClock(LL_AHB1_GRP1_PERIPH_GPIOC);
	/**USART6 GPIO Configuration
  PC6   ------> USART6_TX
  PC7   ------> USART6_RX
	 */
	GPIO_InitStruct.Pin = LL_GPIO_PIN_6|LL_GPIO_PIN_7;
	GPIO_InitStruct.Mode = LL_GPIO_MODE_ALTERNATE;
	GPIO_InitStruct.Speed = LL_GPIO_SPEED_FREQ_VERY_HIGH;
	GPIO_InitStruct.OutputType = LL_GPIO_OUTPUT_PUSHPULL;
	GPIO_InitStruct.Pull = LL_GPIO_PULL_NO;
	GPIO_InitStruct.Alternate = LL_GPIO_AF_8;
	LL_GPIO_Init(GPIOC, &GPIO_InitStruct);

	/* USART6 interrupt Init */
	NVIC_SetPriority(USART6_IRQn, NVIC_EncodePriority(NVIC_GetPriorityGrouping(),0, 0));
	NVIC_EnableIRQ(USART6_IRQn);

	USART_InitStruct.BaudRate = 115200;
	USART_InitStruct.DataWidth = LL_USART_DATAWIDTH_8B;
	USART_InitStruct.StopBits = LL_USART_STOPBITS_1;
	USART_InitStruct.Parity = LL_USART_PARITY_NONE;
	USART_InitStruct.TransferDirection = LL_USART_DIRECTION_TX_RX;
	USART_InitStruct.HardwareFlowControl = LL_USART_HWCONTROL_NONE;
	USART_InitStruct.OverSampling = LL_USART_OVERSAMPLING_16;
	LL_USART_Init(USART6, &USART_InitStruct);
	LL_USART_ConfigAsyncMode(USART6);
	LL_USART_Enable(USART6);

}

static void MX_DMA_Init(void)
{

	/* DMA controller clock enable */
	__HAL_RCC_DMA2_CLK_ENABLE();

	/* DMA interrupt init */
	/* DMA2_Stream0_IRQn interrupt configuration */
	HAL_NVIC_SetPriority(DMA2_Stream0_IRQn, 0, 0);
	HAL_NVIC_EnableIRQ(DMA2_Stream0_IRQn);

}

static void MX_GPIO_Init(void)
{
	LL_GPIO_InitTypeDef GPIO_InitStruct = {0};

	/* GPIO Ports Clock Enable */
	LL_AHB1_GRP1_EnableClock(LL_AHB1_GRP1_PERIPH_GPIOC);
	LL_AHB1_GRP1_EnableClock(LL_AHB1_GRP1_PERIPH_GPIOH);
	LL_AHB1_GRP1_EnableClock(LL_AHB1_GRP1_PERIPH_GPIOA);
	LL_AHB1_GRP1_EnableClock(LL_AHB1_GRP1_PERIPH_GPIOB);
	LL_AHB1_GRP1_EnableClock(LL_AHB1_GRP1_PERIPH_GPIOD);

	/**/
	LL_GPIO_SetOutputPin(GPIOC, LL_GPIO_PIN_13);

	/**/
	LL_GPIO_ResetOutputPin(GPIOC, LL_GPIO_PIN_0|LL_GPIO_PIN_1|LL_GPIO_PIN_2|LL_GPIO_PIN_4
			|LL_GPIO_PIN_9);

	/**/
	LL_GPIO_ResetOutputPin(GPIOB, LL_GPIO_PIN_12|LL_GPIO_PIN_6);

	/**/
	LL_GPIO_ResetOutputPin(GPIOA, LL_GPIO_PIN_8);

	/**/
	GPIO_InitStruct.Pin = LL_GPIO_PIN_13|LL_GPIO_PIN_0|LL_GPIO_PIN_1|LL_GPIO_PIN_2
			|LL_GPIO_PIN_4|LL_GPIO_PIN_9;
	GPIO_InitStruct.Mode = LL_GPIO_MODE_OUTPUT;
	GPIO_InitStruct.Speed = LL_GPIO_SPEED_FREQ_LOW;
	GPIO_InitStruct.OutputType = LL_GPIO_OUTPUT_PUSHPULL;
	GPIO_InitStruct.Pull = LL_GPIO_PULL_NO;
	LL_GPIO_Init(GPIOC, &GPIO_InitStruct);

	/**/
	GPIO_InitStruct.Pin = LL_GPIO_PIN_5|LL_GPIO_PIN_8;
	GPIO_InitStruct.Mode = LL_GPIO_MODE_INPUT;
	GPIO_InitStruct.Pull = LL_GPIO_PULL_NO;
	LL_GPIO_Init(GPIOC, &GPIO_InitStruct);

	/**/
	GPIO_InitStruct.Pin = LL_GPIO_PIN_12|LL_GPIO_PIN_6;
	GPIO_InitStruct.Mode = LL_GPIO_MODE_OUTPUT;
	GPIO_InitStruct.Speed = LL_GPIO_SPEED_FREQ_LOW;
	GPIO_InitStruct.OutputType = LL_GPIO_OUTPUT_PUSHPULL;
	GPIO_InitStruct.Pull = LL_GPIO_PULL_NO;
	LL_GPIO_Init(GPIOB, &GPIO_InitStruct);

	/**/
	GPIO_InitStruct.Pin = LL_GPIO_PIN_8;
	GPIO_InitStruct.Mode = LL_GPIO_MODE_OUTPUT;
	GPIO_InitStruct.Speed = LL_GPIO_SPEED_FREQ_LOW;
	GPIO_InitStruct.OutputType = LL_GPIO_OUTPUT_PUSHPULL;
	GPIO_InitStruct.Pull = LL_GPIO_PULL_NO;
	LL_GPIO_Init(GPIOA, &GPIO_InitStruct);

	/**/
	GPIO_InitStruct.Pin = LL_GPIO_PIN_7;
	GPIO_InitStruct.Mode = LL_GPIO_MODE_INPUT;
	GPIO_InitStruct.Pull = LL_GPIO_PULL_NO;
	LL_GPIO_Init(GPIOB, &GPIO_InitStruct);

}

/* USER CODE BEGIN 4 */
int iBus_Throttle_Min(void)
{
	if (ibus_rx_cplt_flag)
	{
		ibus_rx_cplt_flag = 0;
		if (iBus_Check_CHKSUM(&ibus_rx_buf[0], 32))
		{
			LL_GPIO_TogglePin(GPIOC, LL_GPIO_PIN_2); // toggle LED if iBus frame checksum successful --> intact iBus frame

			iBus_Parse(&ibus_rx_buf[0], &iBus); // parse and store switch/gimbal data in iBus structure

			if (iBus.LV < 1010) return 1;
		}
	}

	return 0;
}

void ESC_Calibration(void)
{
	// set max pulse width
	TIM5->CCR1 = 21000;
	TIM5->CCR2 = 21000;
	TIM5->CCR3 = 21000;
	TIM5->CCR4 = 21000;
	HAL_Delay(7000);

	// set min pulse width
	TIM5->CCR1 = 10500;
	TIM5->CCR2 = 10500;
	TIM5->CCR3 = 10500;
	TIM5->CCR4 = 10500;
	HAL_Delay(8000);
}

void BNO080_Calibration(void)
{
	//Resets BNO080 to disable All output
	BNO080_Initialization();

	//BNO080/BNO085 Configuration
	//Enable dynamic calibration for accelerometer, gyroscope, and magnetometer
	//Enable Game Rotation Vector output
	//Enable Magnetic Field output
	BNO080_calibrateAll(); //Turn on cal for Accel, Gyro, and Mag
	BNO080_enableGameRotationVector(20000); //Send data update every 20ms (50Hz)
	BNO080_enableMagnetometer(20000); //Send data update every 20ms (50Hz)

	//Once magnetic field is 2 or 3, run the Save DCD Now command
	printf("Calibrating BNO080. Pull up FS-i6 SWC to end calibration and save to flash\n");
	printf("Output in form x, y, z, in uTesla\n\n");

	//while loop for calibration procedure
	//Iterates until iBus.SwC is mid point (1500)
	//Calibration procedure should be done while this loop is in iteration.
	while(iBus.SwC == 1500)
	{
		if(BNO080_dataAvailable())
		{
			// get magnetometer data
			float x = BNO080_getMagX();
			float y = BNO080_getMagY();
			float z = BNO080_getMagZ();
			unsigned char accuracy = BNO080_getMagAccuracy();

			// get quaternion data
			float quatI = BNO080_getQuatI();
			float quatJ = BNO080_getQuatJ();
			float quatK = BNO080_getQuatK();
			float quatReal = BNO080_getQuatReal();
			unsigned char sensorAccuracy = BNO080_getQuatAccuracy();

			printf("=== BNO080 Calibration Status ===\n");

			printf("Magnetometer:\n");
			printf(" X: %f  Y: %f  Z: %f\n", x, y, z);
			printf(" Accuracy: ");
			switch(accuracy) {
			case 0: printf("Unreliable\n"); break;
			case 1: printf("Low\n"); break;
			case 2: printf("Medium\n"); break;
			case 3: printf("High\n"); break;
			default: printf("Unknown\n");
			}

			printf("\nQuaternion:\n");
			printf("  I: %f  J: %f  K: %f  Real: %f\n", quatI, quatJ, quatK, sensorAccuracy);
			printf("  Accuracy: ");
			switch(sensorAccuracy) {
			case 0: printf("Unreliable\n"); break;
			case 1: printf("Low\n"); break;
			case 2: printf("Medium\n"); break;
			case 3: printf("High\n"); break;
			default: printf("Unknown\n");
			}

			//Turn the LED and buzzer on when both accuracy and sensorAccuracy is high
			if(accuracy == 3 && sensorAccuracy == 3)
			{
				LL_GPIO_SetOutputPin(GPIOC, LL_GPIO_PIN_0 | LL_GPIO_PIN_1 | LL_GPIO_PIN_2);
				TIM3->PSC = 65000; //Very low frequency
				LL_TIM_CC_EnableChannel(TIM3, LL_TIM_CHANNEL_CH4);
			}
			else
			{
				LL_GPIO_ResetOutputPin(GPIOC, LL_GPIO_PIN_0 | LL_GPIO_PIN_1 | LL_GPIO_PIN_2);
				LL_TIM_CC_DisableChannel(TIM3, LL_TIM_CHANNEL_CH4);
			}
		}

		iBus_Connection_Status(); //Refreshes iBus Data for iBus.SwC
		HAL_Delay(100);
	}

	//Ends the loop when iBus.SwC is not mid point
	//Turn the LED and buzzer off
	LL_GPIO_ResetOutputPin(GPIOC, LL_GPIO_PIN_0 | LL_GPIO_PIN_1 | LL_GPIO_PIN_2);
	LL_TIM_CC_DisableChannel(TIM3, LL_TIM_CHANNEL_CH4);

	//Saves the current dynamic calibration data (DCD) to memory
	//Sends command to get the latest calibration status
	BNO080_saveCalibration();
	BNO080_requestCalibrationStatus();

	//Wait for calibration response, timeout if no response
	int counter = 100;
	while(1)
	{
		if(--counter == 0) break;
		if(BNO080_dataAvailable())
		{
			//The IMU can report many different things. We must wait
			//for the ME Calibration Response Status byte to go to zero
			if(BNO080_calibrationComplete() == 1)
			{
				printf("\nCalibration data successfully stored\n");
				LL_TIM_CC_EnableChannel(TIM3, LL_TIM_CHANNEL_CH4);
				TIM3->PSC = 2000;
				HAL_Delay(300);
				TIM3->PSC = 1500;
				HAL_Delay(300);
				LL_TIM_CC_DisableChannel(TIM3, LL_TIM_CHANNEL_CH4);
				HAL_Delay(1000);
				break;
			}
		}
		HAL_Delay(10);
	}
	if(counter == 0)
	{
		printf("\nCalibration data failed to store. Please try again.\n");
		LL_TIM_CC_EnableChannel(TIM3, LL_TIM_CHANNEL_CH4);
		TIM3->PSC = 1500;
		HAL_Delay(300);
		TIM3->PSC = 2000;
		HAL_Delay(300);
		LL_TIM_CC_DisableChannel(TIM3, LL_TIM_CHANNEL_CH4);
		HAL_Delay(1000);
	}

	//BNO080_endCalibration(); //Turns off all calibration
	//In general, calibration should be left on at all times. The BNO080
	//auto-calibrates and auto-records cal data roughly every 5 minutes

	//Resets BNO080 to disable Game Rotation Vector and Magnetometer
	//Enables Rotation Vector
	BNO080_Initialization();
	BNO080_enableRotationVector(2500); //Send data update every 2.5ms (400Hz)
}

int iBus_Connection_Status(void)
{
	if (ibus_rx_cplt_flag)
	{
		ibus_rx_cplt_flag = 0;
		if (iBus_Check_CHKSUM(&ibus_rx_buf[0], 32))
		{
			iBus_Parse(&ibus_rx_buf[0], &iBus); // parse and store switch/gimbal data in iBus structure
			return 1;
		}
	}

	return 0;
}

void HAL_UART_RxCpltCallback(UART_HandleTypeDef *huart)
{
	static unsigned char cnt = 0;

	if(huart->Instance == USART1)
	{
		HAL_UART_Receive_IT(&huart1, &uart1_rx_data, 1);

		switch(cnt)
		{
		case 0:
			if(uart1_rx_data == 0x47)
			{
				radio_rx_buf[cnt] = uart1_rx_data;
				cnt++;
			}
			break;
		case 1:
			if(uart1_rx_data == 0x53)
			{
				radio_rx_buf[cnt] = uart1_rx_data;
				cnt++;
			}
			else
				cnt = 0;
			break;
		case 19:
			radio_rx_buf[cnt] = uart1_rx_data;
			cnt = 0;
			radio_rx_cplt_flag = 1;
			break;
		default:
			radio_rx_buf[cnt] = uart1_rx_data;
			cnt++;
			break;
		}
	}
}

void Encode_MSG_AHRS(unsigned char *radio_tx_buf)
{
	radio_tx_buf[0] = 0x46;
	radio_tx_buf[1] = 0x43;

	radio_tx_buf[2] = 0x10;

	radio_tx_buf[3] = (short)(BNO080_Roll*100);
	radio_tx_buf[4] = ((short)(BNO080_Roll*100))>>8;

	radio_tx_buf[5] = (short)(BNO080_Pitch*100);
	radio_tx_buf[6] = ((short)(BNO080_Pitch*100))>>8;

	radio_tx_buf[7] = (unsigned short)(BNO080_Yaw*100);
	radio_tx_buf[8] = ((unsigned short)(BNO080_Yaw*100))>>8;

	radio_tx_buf[9] = (short)(LPS22HH.baroAltFilt*10);
	radio_tx_buf[10] = ((short)(LPS22HH.baroAltFilt*10))>>8;

	radio_tx_buf[11] = (short)((iBus.RH-1500)*0.1f*100);
	radio_tx_buf[12] = ((short)((iBus.RH-1500)*0.1f*100))>>8;

	radio_tx_buf[13] = (short)((iBus.RV-1500)*0.1f*100);
	radio_tx_buf[14] = ((short)((iBus.RV-1500)*0.1f*100))>>8;

	radio_tx_buf[15] = (unsigned short)((iBus.LH-1000)*0.36f*100);
	radio_tx_buf[16] = ((unsigned short)((iBus.LH-1000)*0.36f*100))>>8;

	radio_tx_buf[17] = 0x00;
	radio_tx_buf[18] = 0x00;

	radio_tx_buf[19] = 0xff;

	for (int i = 0; i < 19; i++) radio_tx_buf[19] = radio_tx_buf[19] - radio_tx_buf[i];
}

void Encode_MSG_GPS(unsigned char *radio_tx_buf)
{
	radio_tx_buf[0] = 0x46;
	radio_tx_buf[1] = 0x43;

	radio_tx_buf[2] = 0x11;

	radio_tx_buf[3] = 0x00;
	radio_tx_buf[4] = 0x00;
	radio_tx_buf[5] = 0x00;
	radio_tx_buf[6] = 0x00;

	radio_tx_buf[7] = 0x00;
	radio_tx_buf[8] = 0x00;
	radio_tx_buf[9] = 0x00;
	radio_tx_buf[10] = 0x00;

	radio_tx_buf[11] = (unsigned short)(batVolt*100);
	radio_tx_buf[12] = ((unsigned short)(batVolt*100)>>8);

	radio_tx_buf[13] = iBus.SwA == 1000 ? 0 : 1;
	radio_tx_buf[14] = iBus.SwC == 1000 ? 0 : iBus.SwC == 1500 ? 1 : 2;

	radio_tx_buf[15] = failsafe_flag;

	radio_tx_buf[16] = 0x00;
	radio_tx_buf[17] = 0x00;
	radio_tx_buf[18] = 0x00;

	radio_tx_buf[19] = 0xff;

	for (int i = 0; i < 19; i++) radio_tx_buf[19] = radio_tx_buf[19] - radio_tx_buf[i];
}

void Encode_MSG_PID_Gain(unsigned char *radio_tx_buf, unsigned char id, float p, float i, float d)
{
	radio_tx_buf[0] = 0x46;
	radio_tx_buf[1] = 0x43;

	radio_tx_buf[2] = id;

	//	memcpy(&radio_tx_buf[3], &p, 4);
	//
	//	memcpy(&radio_tx_buf[7], &i, 4);
	//
	//	memcpy(&radio_tx_buf[11], &d, 4);

	*(float *)&radio_tx_buf[3] = p;
	*(float *)&radio_tx_buf[7] = i;
	*(float *)&radio_tx_buf[11] = d;

	radio_tx_buf[15] = 0x00;
	radio_tx_buf[16] = 0x00;
	radio_tx_buf[17] = 0x00;
	radio_tx_buf[18] = 0x00;

	radio_tx_buf[19] = 0xff;

	for (int i = 0; i < 19; i++) radio_tx_buf[19] = radio_tx_buf[19] - radio_tx_buf[i];
}
/* USER CODE END 4 */

void Error_Handler(void)
{
	__disable_irq();
	while (1)
	{
	}
}
